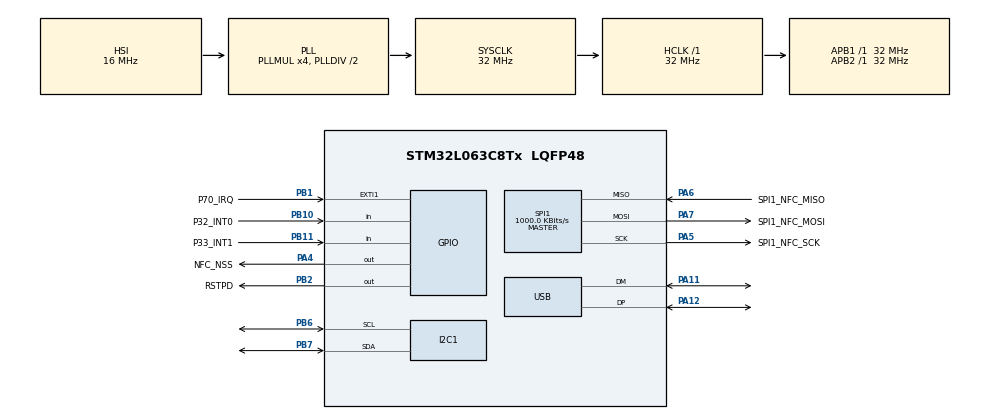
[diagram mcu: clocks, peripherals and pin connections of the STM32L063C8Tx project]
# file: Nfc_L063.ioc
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I2C1.Timing=0x00707CBB
Mcu.Family=STM32L0
Mcu.Name=STM32L063C8Tx
Mcu.Package=LQFP48
NVIC.USB_IRQn=true\:0\:0\:false\:false\:true\:false\:true
PA11.Mode=Device
PA11.Signal=USB_DM
PA12.Mode=Device
PA12.Signal=USB_DP
PA13.Mode=Serial_Wire
PA13.Signal=SYS_SWDIO
PA14.Mode=Serial_Wire
PA14.Signal=SYS_SWCLK
PA4.GPIO_Label=NFC_NSS
PA4.Signal=GPIO_Output
PA5.GPIO_Label=SPI1_NFC_SCK
PA5.Mode=Full_Duplex_Master
PA5.Signal=SPI1_SCK
PA6.GPIO_Label=SPI1_NFC_MISO
PA6.Mode=Full_Duplex_Master
PA6.Signal=SPI1_MISO
PA7.GPIO_Label=SPI1_NFC_MOSI
PA7.Mode=Full_Duplex_Master
PA7.Signal=SPI1_MOSI
PB1.GPIO_Label=P70_IRQ
PB1.Signal=GPXTI1
PB10.GPIO_Label=P32_INT0
PB10.Signal=GPIO_Input
PB11.GPIO_Label=P33_INT1
PB11.Signal=GPIO_Input
PB2.GPIO_Label=RSTPD
PB2.Signal=GPIO_Output
PB6.Mode=I2C
PB6.Signal=I2C1_SCL
PB7.Mode=I2C
PB7.Signal=I2C1_SDA
ProjectManager.HeapSize=0x200
ProjectManager.StackSize=0x400
ProjectManager.TargetToolchain=STM32CubeIDE
RCC.AHBFreq_Value=32000000
RCC.APB1Freq_Value=32000000
RCC.APB1TimFreq_Value=32000000
RCC.APB2Freq_Value=32000000
RCC.APB2TimFreq_Value=32000000
RCC.HCLKFreq_Value=32000000
RCC.HSE_VALUE=8000000
RCC.HSI16_VALUE=16000000
RCC.HSI48MClockSelection=RCC_USBCLKSOURCE_HSI48
RCC.HSI48_VALUE=48000000
RCC.HSI_VALUE=16000000
RCC.LSE_VALUE=32768
RCC.MSI_VALUE=2097000
RCC.PLLMUL=RCC_PLLMUL_4
RCC.SYSCLKFreq_VALUE=32000000
RCC.SYSCLKSource=RCC_SYSCLKSOURCE_PLLCLK
RCC.VCOOutputFreq_Value=64000000
SPI1.BaudRatePrescaler=SPI_BAUDRATEPRESCALER_32
SPI1.CalculateBaudRate=1000.0 KBits/s
SPI1.Direction=SPI_DIRECTION_2LINES
SPI1.FirstBit=SPI_FIRSTBIT_LSB
SPI1.Mode=SPI_MODE_MASTER
SPI1.VirtualType=VM_MASTER
TIM6.Period=10000
TIM6.Prescaler=32
USB_DEVICE.CLASS_NAME_FS=CDC
USB_DEVICE.VirtualMode=Cdc
USB_DEVICE.VirtualModeFS=Cdc_FS
VP_RNG_VS_RNG.Mode=RNG_Activate
VP_TIM6_VS_ClockSourceINT.Mode=Enable_Timer
VP_USB_DEVICE_VS_USB_DEVICE_CDC_FS.Mode=CDC_FS
board=custom

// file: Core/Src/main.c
/* USER CODE BEGIN Header */
/**
  ******************************************************************************
  * @file           : main.c
  * @brief          : Main program body
  ******************************************************************************
  * @attention
  *
  * <h2><center>&copy; Copyright (c) 2021 STMicroelectronics.
  * All rights reserved.</center></h2>
  *
  * This software component is licensed by ST under BSD 3-Clause license,
  * the "License"; You may not use this file except in compliance with the
  * License. You may obtain a copy of the License at:
  *                        opensource.org/licenses/BSD-3-Clause
  *
  ******************************************************************************
  */
/* USER CODE END Header */
#include "main.h"
#include "usb_device.h"

I2C_HandleTypeDef hi2c1;

RNG_HandleTypeDef hrng;

SPI_HandleTypeDef hspi1;

TIM_HandleTypeDef htim6;

void SystemClock_Config(void);
static void MX_GPIO_Init(void);
static void MX_I2C1_Init(void);
static void MX_SPI1_Init(void);
static void MX_RNG_Init(void);
static void MX_TIM6_Init(void);

int main(void)
{

  /* MCU Configuration--------------------------------------------------------*/

  /* Reset of all peripherals, Initializes the Flash interface and the Systick. */
  HAL_Init();

  /* Configure the system clock */
  SystemClock_Config();

  /* Initialize all configured peripherals */
  MX_GPIO_Init();
  MX_I2C1_Init();
  MX_SPI1_Init();
  MX_USB_DEVICE_Init();
  MX_RNG_Init();
  MX_TIM6_Init();

  /* Infinite loop */
  /* USER CODE BEGIN WHILE */
  while (1)
  {
	  NFC_Cycle();
    /* USER CODE END WHILE */

  }
}

void SystemClock_Config(void)
{
  RCC_OscInitTypeDef RCC_OscInitStruct = {0};
  RCC_ClkInitTypeDef RCC_ClkInitStruct = {0};
  RCC_PeriphCLKInitTypeDef PeriphClkInit = {0};

  /** Configure the main internal regulator output voltage
  */
  __HAL_PWR_VOLTAGESCALING_CONFIG(PWR_REGULATOR_VOLTAGE_SCALE1);
  /** Initializes the RCC Oscillators according to the specified parameters
  * in the RCC_OscInitTypeDef structure.
  */
  RCC_OscInitStruct.OscillatorType = RCC_OSCILLATORTYPE_HSI|RCC_OSCILLATORTYPE_HSI48;
  RCC_OscInitStruct.HSIState = RCC_HSI_ON;
  RCC_OscInitStruct.HSICalibrationValue = RCC_HSICALIBRATION_DEFAULT;
  RCC_OscInitStruct.HSI48State = RCC_HSI48_ON;
  RCC_OscInitStruct.PLL.PLLState = RCC_PLL_ON;
  RCC_OscInitStruct.PLL.PLLSource = RCC_PLLSOURCE_HSI;
  RCC_OscInitStruct.PLL.PLLMUL = RCC_PLLMUL_4;
  RCC_OscInitStruct.PLL.PLLDIV = RCC_PLLDIV_2;
  if (HAL_RCC_OscConfig(&RCC_OscInitStruct) != HAL_OK)
  {
    Error_Handler();
  }
  /** Initializes the CPU, AHB and APB buses clocks
  */
  RCC_ClkInitStruct.ClockType = RCC_CLOCKTYPE_HCLK|RCC_CLOCKTYPE_SYSCLK
                              |RCC_CLOCKTYPE_PCLK1|RCC_CLOCKTYPE_PCLK2;
  RCC_ClkInitStruct.SYSCLKSource = RCC_SYSCLKSOURCE_PLLCLK;
  RCC_ClkInitStruct.AHBCLKDivider = RCC_SYSCLK_DIV1;
  RCC_ClkInitStruct.APB1CLKDivider = RCC_HCLK_DIV1;
  RCC_ClkInitStruct.APB2CLKDivider = RCC_HCLK_DIV1;

  if (HAL_RCC_ClockConfig(&RCC_ClkInitStruct, FLASH_LATENCY_1) != HAL_OK)
  {
    Error_Handler();
  }
  PeriphClkInit.PeriphClockSelection = RCC_PERIPHCLK_I2C1|RCC_PERIPHCLK_USB;
  PeriphClkInit.I2c1ClockSelection = RCC_I2C1CLKSOURCE_PCLK1;
  PeriphClkInit.UsbClockSelection = RCC_USBCLKSOURCE_HSI48;
  if (HAL_RCCEx_PeriphCLKConfig(&PeriphClkInit) != HAL_OK)
  {
    Error_Handler();
  }
}

static void MX_I2C1_Init(void)
{

  hi2c1.Instance = I2C1;
  hi2c1.Init.Timing = 0x00707CBB;
  hi2c1.Init.OwnAddress1 = 0;
  hi2c1.Init.AddressingMode = I2C_ADDRESSINGMODE_7BIT;
  hi2c1.Init.DualAddressMode = I2C_DUALADDRESS_DISABLE;
  hi2c1.Init.OwnAddress2 = 0;
  hi2c1.Init.OwnAddress2Masks = I2C_OA2_NOMASK;
  hi2c1.Init.GeneralCallMode = I2C_GENERALCALL_DISABLE;
  hi2c1.Init.NoStretchMode = I2C_NOSTRETCH_DISABLE;
  if (HAL_I2C_Init(&hi2c1) != HAL_OK)
  {
    Error_Handler();
  }
  /** Configure Analogue filter
  */
  if (HAL_I2CEx_ConfigAnalogFilter(&hi2c1, I2C_ANALOGFILTER_ENABLE) != HAL_OK)
  {
    Error_Handler();
  }
  /** Configure Digital filter
  */
  if (HAL_I2CEx_ConfigDigitalFilter(&hi2c1, 0) != HAL_OK)
  {
    Error_Handler();
  }

}

static void MX_RNG_Init(void)
{

  hrng.Instance = RNG;
  if (HAL_RNG_Init(&hrng) != HAL_OK)
  {
    Error_Handler();
  }

}

static void MX_SPI1_Init(void)
{

  /* SPI1 parameter configuration*/
  hspi1.Instance = SPI1;
  hspi1.Init.Mode = SPI_MODE_MASTER;
  hspi1.Init.Direction = SPI_DIRECTION_2LINES;
  hspi1.Init.DataSize = SPI_DATASIZE_8BIT;
  hspi1.Init.CLKPolarity = SPI_POLARITY_LOW;
  hspi1.Init.CLKPhase = SPI_PHASE_1EDGE;
  hspi1.Init.NSS = SPI_NSS_SOFT;
  hspi1.Init.BaudRatePrescaler = SPI_BAUDRATEPRESCALER_32;
  hspi1.Init.FirstBit = SPI_FIRSTBIT_LSB;
  hspi1.Init.TIMode = SPI_TIMODE_DISABLE;
  hspi1.Init.CRCCalculation = SPI_CRCCALCULATION_DISABLE;
  hspi1.Init.CRCPolynomial = 7;
  if (HAL_SPI_Init(&hspi1) != HAL_OK)
  {
    Error_Handler();
  }

}

static void MX_TIM6_Init(void)
{

  TIM_MasterConfigTypeDef sMasterConfig = {0};

  htim6.Instance = TIM6;
  htim6.Init.Prescaler = 32;
  htim6.Init.CounterMode = TIM_COUNTERMODE_UP;
  htim6.Init.Period = 10000;
  htim6.Init.AutoReloadPreload = TIM_AUTORELOAD_PRELOAD_DISABLE;
  if (HAL_TIM_Base_Init(&htim6) != HAL_OK)
  {
    Error_Handler();
  }
  sMasterConfig.MasterOutputTrigger = TIM_TRGO_RESET;
  sMasterConfig.MasterSlaveMode = TIM_MASTERSLAVEMODE_DISABLE;
  if (HAL_TIMEx_MasterConfigSynchronization(&htim6, &sMasterConfig) != HAL_OK)
  {
    Error_Handler();
  }

}

static void MX_GPIO_Init(void)
{
  GPIO_InitTypeDef GPIO_InitStruct = {0};

  /* GPIO Ports Clock Enable */
  __HAL_RCC_GPIOA_CLK_ENABLE();
  __HAL_RCC_GPIOB_CLK_ENABLE();

  /*Configure GPIO pin Output Level */
  HAL_GPIO_WritePin(NFC_NSS_GPIO_Port, NFC_NSS_Pin, GPIO_PIN_RESET);

  /*Configure GPIO pin Output Level */
  HAL_GPIO_WritePin(RSTPD_GPIO_Port, RSTPD_Pin, GPIO_PIN_RESET);

  /*Configure GPIO pin : NFC_NSS_Pin */
  GPIO_InitStruct.Pin = NFC_NSS_Pin;
  GPIO_InitStruct.Mode = GPIO_MODE_OUTPUT_PP;
  GPIO_InitStruct.Pull = GPIO_NOPULL;
  GPIO_InitStruct.Speed = GPIO_SPEED_FREQ_LOW;
  HAL_GPIO_Init(NFC_NSS_GPIO_Port, &GPIO_InitStruct);

  /*Configure GPIO pin : P70_IRQ_Pin */
  GPIO_InitStruct.Pin = P70_IRQ_Pin;
  GPIO_InitStruct.Mode = GPIO_MODE_IT_RISING;
  GPIO_InitStruct.Pull = GPIO_NOPULL;
  HAL_GPIO_Init(P70_IRQ_GPIO_Port, &GPIO_InitStruct);

  /*Configure GPIO pin : RSTPD_Pin */
  GPIO_InitStruct.Pin = RSTPD_Pin;
  GPIO_InitStruct.Mode = GPIO_MODE_OUTPUT_PP;
  GPIO_InitStruct.Pull = GPIO_NOPULL;
  GPIO_InitStruct.Speed = GPIO_SPEED_FREQ_LOW;
  HAL_GPIO_Init(RSTPD_GPIO_Port, &GPIO_InitStruct);

  /*Configure GPIO pins : P32_INT0_Pin P33_INT1_Pin */
  GPIO_InitStruct.Pin = P32_INT0_Pin|P33_INT1_Pin;
  GPIO_InitStruct.Mode = GPIO_MODE_INPUT;
  GPIO_InitStruct.Pull = GPIO_NOPULL;
  HAL_GPIO_Init(GPIOB, &GPIO_InitStruct);

}

void Error_Handler(void)
{
  __disable_irq();
  while (1)
  {
  }
}

/************************ (C) COPYRIGHT STMicroelectronics *****END OF FILE****/
